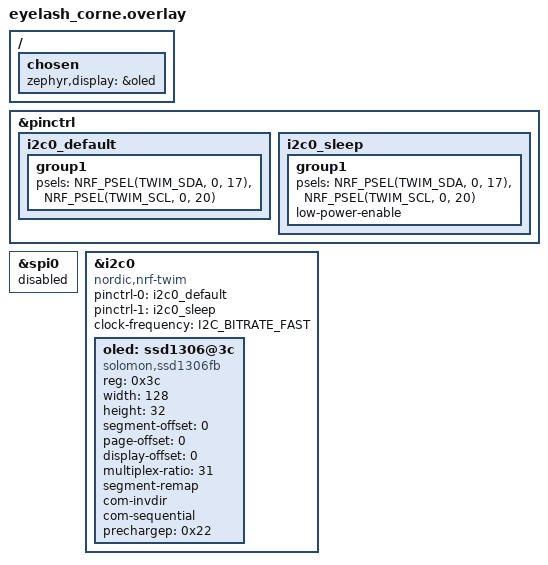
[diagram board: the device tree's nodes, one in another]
/*
 * Copyright (c) 2024 The ZMK Contributors
 *
 * SPDX-License-Identifier: MIT
 */

&pinctrl {
    i2c0_default: i2c0_default {
        group1 {
            psels = <NRF_PSEL(TWIM_SDA, 0, 17)>,
                    <NRF_PSEL(TWIM_SCL, 0, 20)>;
        };
    };
    i2c0_sleep: i2c0_sleep {
        group1 {
            psels = <NRF_PSEL(TWIM_SDA, 0, 17)>,
                    <NRF_PSEL(TWIM_SCL, 0, 20)>;
            low-power-enable;
        };
    };
};

&spi0 { status = "disabled"; };

&i2c0 {
    status = "okay";
    compatible = "nordic,nrf-twim";
    pinctrl-0 = <&i2c0_default>;
    pinctrl-1 = <&i2c0_sleep>;
    pinctrl-names = "default", "sleep";
    clock-frequency = <I2C_BITRATE_FAST>;

    oled: ssd1306@3c {
        compatible = "solomon,ssd1306fb";
        reg = <0x3c>;
        width = <128>;
        height = <32>;
        segment-offset = <0>;
        page-offset = <0>;
        display-offset = <0>;
        multiplex-ratio = <31>;
        segment-remap;
        com-invdir;
        com-sequential;
        prechargep = <0x22>;
    };
};

/ {
    chosen {
        zephyr,display = &oled;
    };
};
